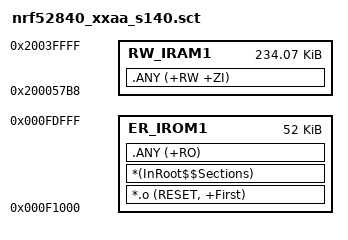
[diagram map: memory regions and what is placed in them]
; *************************************************************
; *** Scatter-Loading Description File generated by uVision ***
; *************************************************************

LR_IROM1 0x000F1000 0x0000D000  {    ; load region size_region
  ER_IROM1 0x000F1000 0x0000D000  {  ; load address = execution address
   *.o (RESET, +First)
   *(InRoot$$Sections)
   .ANY (+RO)
  }
  RW_IRAM1 0x200057B8 0x0003A848  {  ; RW data
   .ANY (+RW +ZI)
  }
}

